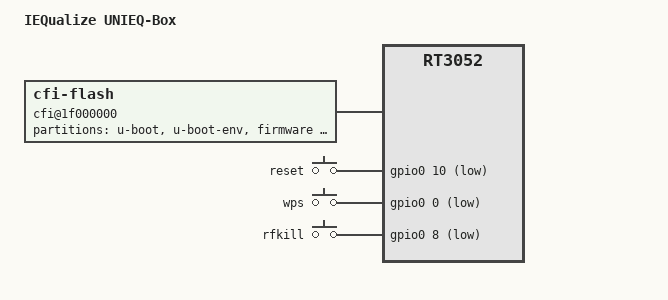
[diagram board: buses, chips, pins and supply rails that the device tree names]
/dts-v1/;

/include/ "rt3050.dtsi"

/ {
	compatible = "UNIEQ-Box", "ralink,rt3052-soc";
	model = "IEQualize UNIEQ-Box";

	pinctrl {
		state_default: pinctrl0 {
			gpio {
				ralink,group = "spi", "i2c", "jtag", "uartf";
				ralink,function = "gpio";
			};
			rgmii {
				ralink,group = "rgmii";
				ralink,function = "rgmii";
			};
			mdio {
				ralink,group = "mdio";
				ralink,function = "mdio";
			};
		};
	};

	cfi@1f000000 {
		compatible = "cfi-flash";
		reg = <0x1f000000 0x800000>;

		bank-width = <2>;
		device-width = <2>;
		#address-cells = <1>;
		#size-cells = <1>;

		partition@0 {
			label = "u-boot";
			reg = <0x0 0x30000>;
			read-only;
		};

		partition@30000 {
			label = "u-boot-env";
			reg = <0x30000 0x10000>;
		};

		partition@40000 {
			label = "firmware";
			reg = <0x40000 0x6c0000>;
		};

		partition@700000 {
			label = "data";
			reg = <0x700000 0x100000>;
		};
	};

	esw@10110000 {
		/*
		 * PLC module is connected to port 5
		 * U-Boot default seems to be 0x18503ff9 0x18503c39;
		 */
		ralink,fpa2 = <0x18503ff9>;
	};

	gpio-keys-polled {
		compatible = "gpio-keys-polled";
		#address-cells = <1>;
		#size-cells = <0>;
		poll-interval = <20>;

		reset {
			label = "reset";
			gpios = <&gpio0 10 1>;
			linux,code = <0x198>;
		};

		wps {
			label = "wps";
			gpios = <&gpio0 0 1>;
			linux,code = <0x211>;
		};

		rfkill {
			label = "rfkill";
			gpios = <&gpio0 8 1>;
			linux,code = <0xf7>;
		};
	};
};
